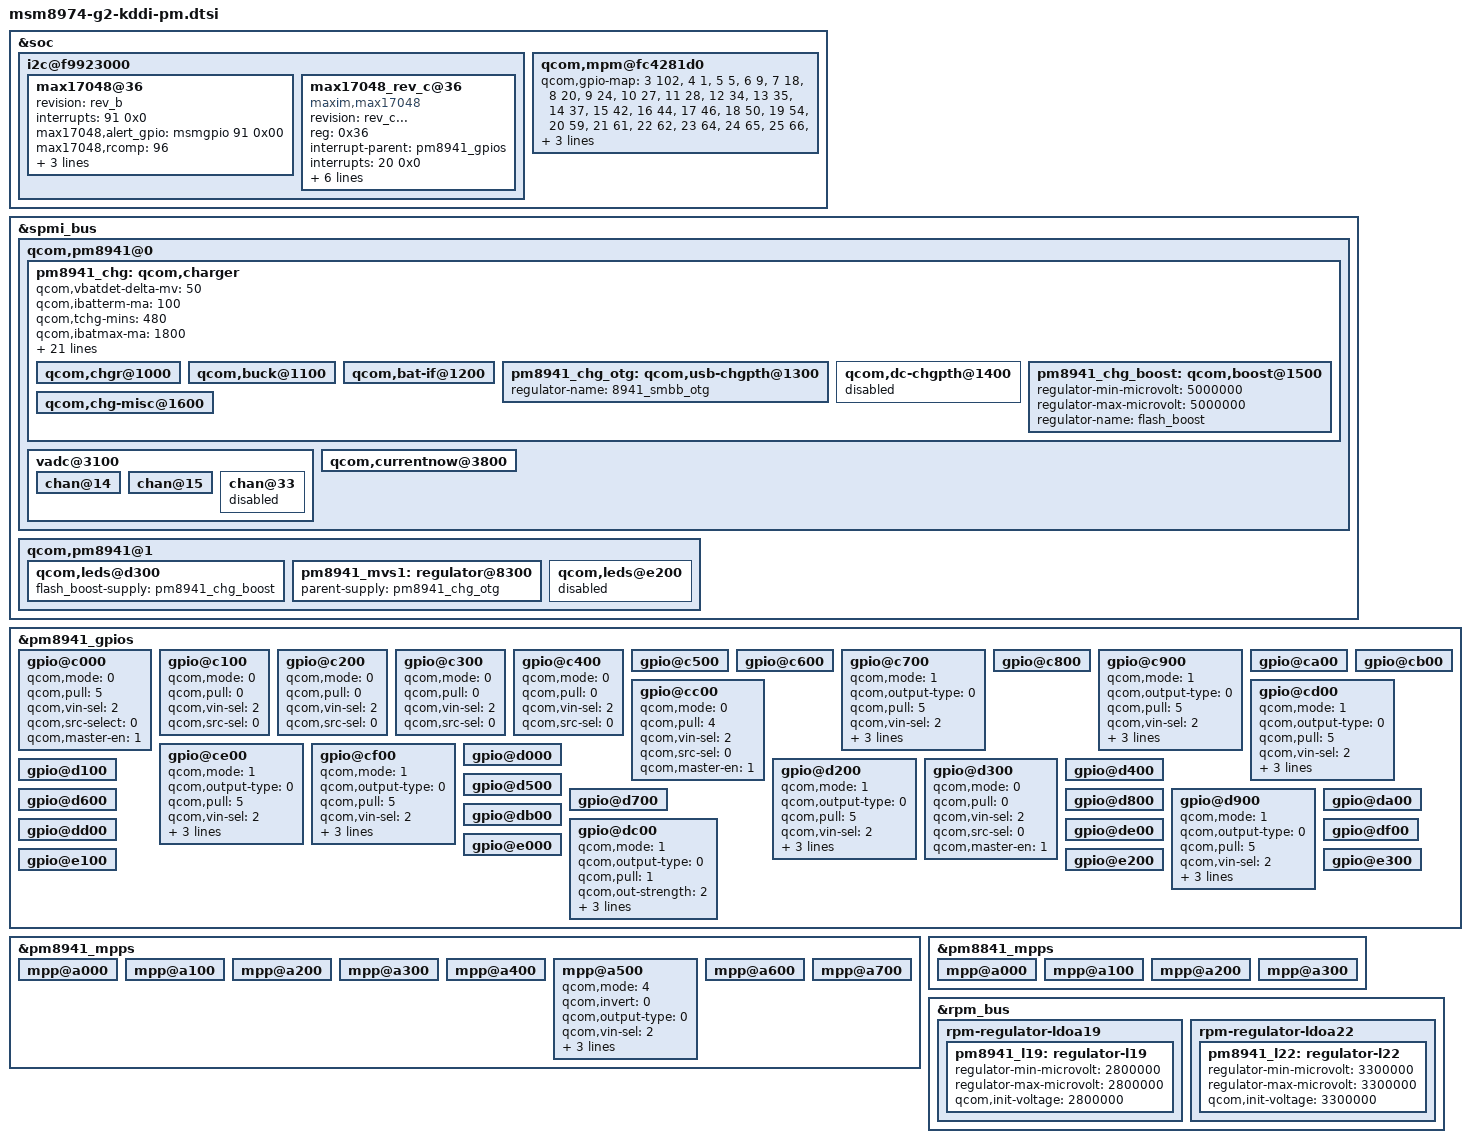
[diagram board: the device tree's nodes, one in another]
/* Copyright (c) 2012, Code Aurora Forum. All rights reserved.
 *
 * This program is free software; you can redistribute it and/or modify
* it under the terms of the GNU General Public License version 2 and
* only version 2 as published by the Free Software Foundation.
*
* This program is distributed in the hope that it will be useful,
* but WITHOUT ANY WARRANTY; without even the implied warranty of
* MERCHANTABILITY or FITNESS FOR A PARTICULAR PURPOSE.  See the
* GNU General Public License for more details.
*/

&soc {
	i2c@f9923000 {
		max17048@36 {
			status =  "ok";
			revision = "rev_b";
			interrupts = <91 0x0>;
			max17048,alert_gpio = <&msmgpio 91 0x00>;
			max17048,rcomp = <96>;
			max17048,temp_co_hot = <25>;
			max17048,temp_co_cold = <7400>;
			max17048,full_design = <2540>;
		};

		max17048_rev_c@36 {
			compatible = "maxim,max17048";
			status =  "ok";
			revision = "rev_c...";
			reg = <0x36>;
			interrupt-parent = <&pm8941_gpios>;
			interrupts = <20 0x0>;
			max17048,alert_gpio = <&pm8941_gpios 20 0x00>;
			max17048,alert_threshold = <2>;
			max17048,rcomp = <96>;
			max17048,temp_co_hot = <25>;
			max17048,temp_co_cold = <7400>;
			max17048,full_design = <2540>;
		};
	};

	qcom,mpm@fc4281d0 {
		/* overrides wakeup gpio source for NFC */
		qcom,gpio-map = <3  102>,
			<4  1 >,
			<5  5 >,
			<6  9 >,
			<7  18>,
			<8  20>,
			<9  24>,
			<10  27>,
			<11  28>,
			<12  34>,
			<13  35>,
			<14  37>,
			<15  42>,
			<16  44>,
			<17  46>,
			<18  50>,
			<19  54>,
			<20  59>,
			<21  61>,
			<22  62>,
			<23  64>,
			<24  65>,
			<25  66>,
			<26  67>,
			<27  68>,
			<28  71>,
			<29  72>,
			<30  73>,
			<31  74>,
			<32  75>,
			<33  77>,
			<34  79>,
			<35  80>,
			<36  82>,
			<37  86>,
			<38  92>,
			<39  93>,
			<40  95>,
			<41  144>,
			<42  94>; /* SNFC_IMA_INTU */
	};
};

&spmi_bus {
	qcom,pm8941@0 {
		pm8941_chg: qcom,charger {
			status = "ok";
			qcom,vbatdet-delta-mv = <50>;
			qcom,ibatterm-ma = <100>;
			qcom,tchg-mins = <480>;
			qcom,ibatmax-ma = <1800>;
			qcom,ibatsafe-ma = <1800>;
			qcom,vddmax-mv = <4350>;
			qcom,vddsafe-mv = <4380>;
			qcom,bpd-detection = "bpd_thm";
			qcom,duty-cycle-100p = <1>;
			otg-parent-supply = <&pm8941_boost>;

			lge,no-init-cable = <0 0 0>;
			lge,cable-mhl-1k = <5000 500 500>;
			lge,cable-u-28p7k = <5500 1600 500>;
			lge,cable-28p7k = <6000 1600 500>;
			lge,cable-56k = <200000 1500 1500>;
			lge,cable-100k = <239000 1600 500>;
			lge,cable-130k = <340000 1500 1500>;
			lge,cable-180k = <400000 1600 500>;
			lge,cable-200k = <410000 1600 500>;
			lge,cable-220k = <485000 1600 500>;
			lge,cable-270k = <560000 1600 500>;
			lge,cable-330k = <735000 1600 500>;
			lge,cable-620k = <955000 1600 500>;
			lge,cable-910k = <1140000 1500 1500>;
			lge,cable-none = <1900000 1600  500>;

			qcom,chgr@1000 {
				status = "ok";
			};

			qcom,buck@1100 {
				status = "ok";
			};

			qcom,bat-if@1200 {
				status = "ok";
			};

			pm8941_chg_otg: qcom,usb-chgpth@1300 {
				status = "ok";
				regulator-name = "8941_smbb_otg";
			};

			qcom,dc-chgpth@1400 {
				status = "disabled";
			};

			pm8941_chg_boost: qcom,boost@1500 {
				status = "ok";
				regulator-min-microvolt = <5000000>;
				regulator-max-microvolt = <5000000>;
				regulator-name = "flash_boost";
			};

			qcom,chg-misc@1600 {
				status = "ok";
			};

		};

		vadc@3100 {
			chan@14 {
				status = "ok";
			};
			chan@15 {
				status = "ok";
			};
			chan@33 {
				status = "disable";
			};
		};
		qcom,currentnow@3800 {
			status = "ok";
		};
	};

	qcom,pm8941@1 {
		qcom,leds@d300 {
			flash_boost-supply = <&pm8941_chg_boost>;
		};

		pm8941_mvs1: regulator@8300 {
			parent-supply = <&pm8941_chg_otg>;
		};

		qcom,leds@e200 {
			status = "disabled";
		};

	};
};

&pm8941_gpios {
	gpio@c000 { /* GPIO 1 */
		status = "ok";
		qcom,mode = <0>;
		qcom,pull = <5>;
		qcom,vin-sel = <2>;
		qcom,src-select = <0>;
		qcom,master-en = <1>;
	};

	gpio@c100 { /* GPIO 2 */
		qcom,mode = <0>;
		qcom,pull = <0>;
		qcom,vin-sel = <2>;
		qcom,src-sel = <0>;
	};

	gpio@c200 { /* GPIO 3 */
		qcom,mode = <0>;
		qcom,pull = <0>;
		qcom,vin-sel = <2>;
		qcom,src-sel = <0>;
	};

	gpio@c300 { /* GPIO 4 */
		qcom,mode = <0>;
		qcom,pull = <0>;
		qcom,vin-sel = <2>;
		qcom,src-sel = <0>;
	};

	gpio@c400 { /* GPIO 5 */
		qcom,mode = <0>;
		qcom,pull = <0>;
		qcom,vin-sel = <2>;
		qcom,src-sel = <0>;
	};

	gpio@c500 { /* GPIO 6 */
	};

	gpio@c600 { /* GPIO 7 */
	};

	gpio@c700 { /* GPIO 8 */
		status = "ok";
		qcom,mode = <1>;		/* QPNP_PIN_MODE_DIG_OUT */
		qcom,output-type = <0>;		/* QPNP_PIN_OUT_BUF_CMOS */
		qcom,pull = <5>;		/* QPNP_PIN_PULL_NO */
		qcom,vin-sel = <2>;		/* QPNP_PIN_VIN2 */
		qcom,out-strength = <2>;	/* QPNP_PIN_OUT_STRENGTH_MED */
		qcom,src-select = <0>;		/* QPNP_PIN_SEL_FUNC_CONSTANT */
		qcom,master-en = <1>;
	};

	gpio@c800 { /* GPIO 9 */
	};

	gpio@c900 { /* GPIO 10 */
		status = "ok";
		qcom,mode = <1>;		/* QPNP_PIN_MODE_DIG_OUT */
		qcom,output-type = <0>;		/* QPNP_PIN_OUT_BUF_CMOS */
		qcom,pull = <5>;		/* QPNP_PIN_PULL_NO */
		qcom,vin-sel = <2>;		/* QPNP_PIN_VIN2 */
		qcom,out-strength = <2>;	/* QPNP_PIN_OUT_STRENGTH_MED */
		qcom,src-select = <0>;		/* QPNP_PIN_SEL_FUNC_CONSTANT */
		qcom,master-en = <1>;
	};

	gpio@ca00 { /* GPIO 11 */
	};

	gpio@cb00 { /* GPIO 12 */
	};

	gpio@cc00 { /* GPIO 13 */ /* LGE_CHANGE, SlimPort Cable Det IRQ */
		status = "ok";
		qcom,mode = <0>;		/* QPNP_PIN_MODE_DIG_IN */
		qcom,pull = <4>;		/* QPNP_PIN_PULL_DN */
		qcom,vin-sel = <2>;		/* QPNP_PIN_VIN2 */
		qcom,src-sel = <0>;		/* QPNP_PIN_SEL_FUNC_CONSTANT */
		qcom,master-en = <1>;
	};

	gpio@cd00 { /* GPIO 14 */ /* LGE_CHANGE, SlimPort PWR Ctl Pin Setting */
		status = "ok";
		qcom,mode = <1>;		/* QPNP_PIN_MODE_DIG_OUT */
		qcom,output-type = <0>;		/* QPNP_PIN_OUT_BUF_CMOS */
		qcom,pull = <5>;		/* QPNP_PIN_PULL_NO */
		qcom,vin-sel = <2>;		/* QPNP_PIN_VIN2 */
		qcom,out-strength = <2>;	/* QPNP_PIN_OUT_STRENGTH_MED */
		qcom,src-sel = <0>;		/* QPNP_PIN_SEL_FUNC_CONSTANT */
		qcom,master-en = <1>;
	};

	gpio@ce00 { /* GPIO 15 */
		qcom,mode = <1>;
		qcom,output-type = <0>;
		qcom,pull = <5>;
		qcom,vin-sel = <2>;
		qcom,out-strength = <3>;
		qcom,src-sel = <2>;
		qcom,master-en = <1>;
	};

	gpio@cf00 { /* GPIO 16 */ /* LGE_CHANGE, [BT][younghyun.kwon@lge.com], 2013-02-26, BT Sleep clock(32KHz) configuration*/
		qcom,mode = <1>;
		qcom,output-type = <0>;
		qcom,pull = <5>;
		qcom,vin-sel = <2>;
		qcom,out-strength = <3>;
		qcom,src-sel = <3>;
		qcom,master-en = <1>;
	};

	gpio@d000 { /* GPIO 17 */
	};

	gpio@d100 { /* GPIO 18 */
	};

	gpio@d200 { /* GPIO 19 */
		qcom,mode = <1>;		/* QPNP_PIN_MODE_DIG_OUT */
		qcom,output-type = <0>;		/* QPNP_PIN_OUT_BUF_CMOS */
		qcom,pull = <5>;		/* QPNP_PIN_PULL_NO */
		qcom,vin-sel = <2>;		/* QPNP_PIN_VIN2 */
		qcom,out-strength = <2>;	/* QPNP_PIN_OUT_STRENGTH_MED */
		qcom,src-sel = <0>;		/* QPNP_PIN_SEL_FUNC_CONSTANT */
		qcom,master-en = <1>;
	};

	gpio@d300 { /* GPIO 20 */
		status = "ok";
		qcom,mode = <0>;		/* QPNP_PIN_MODE_DIG_IN */
		qcom,pull = <0>;		/* QPNP_PIN_PULL_UP_30 */
		qcom,vin-sel = <2>;		/* QPNP_PIN_VIN2 */
		qcom,src-sel = <0>;		/* QPNP_PIN_SEL_FUNC_CONSTANT */
		qcom,master-en = <1>;
	};

	gpio@d400 { /* GPIO 21 */
	};

	gpio@d500 { /* GPIO 22 */
	};

	gpio@d600 { /* GPIO 23 */
	};

	gpio@d700 { /* GPIO 24 */
	};

	gpio@d800 { /* GPIO 25 */
	};

	gpio@d900 { /* GPIO 26 */
		status = "ok";
		qcom,mode = <1>;		/* QPNP_PIN_MODE_DIG_OUT */
		qcom,output-type = <0>;		/* QPNP_PIN_OUT_BUF_CMOS */
		qcom,pull = <5>;		/* QPNP_PIN_PULL_NO */
		qcom,vin-sel = <2>;		/* QPNP_PIN_VIN2 */
		qcom,out-strength = <2>;	/* QPNP_PIN_OUT_STRENGTH_MED */
		qcom,src-select = <0>;		/* QPNP_PIN_SEL_FUNC_CONSTANT */
		qcom,master-en = <1>;
	};

	gpio@da00 { /* GPIO 27 */
	};

	gpio@db00 { /* GPIO 28 */
	};

	gpio@dc00 { /* GPIO 29 */
		status = "ok";
		qcom,mode = <1>;
		qcom,output-type = <0>;
		qcom,pull = <1>; /* set to default pull */
		qcom,out-strength = <2>;
		com,vin-sel = <2>; /* select 1.8 V source */
		qcom,src-select = <0>;      /* QPNP_PIN_SEL_FUNC_CONSTANT */
		qcom,master-en = <1>;
	};

	gpio@dd00 { /* GPIO 30 */
	};

	gpio@de00 { /* GPIO 31 */
	};

	gpio@df00 { /* GPIO 32 */
	};

	gpio@e000 { /* GPIO 33 */
	};

	gpio@e100 { /* GPIO 34 */
	};

	gpio@e200 { /* GPIO 35 */
	};

	gpio@e300 { /* GPIO 36 */
	};
};

&pm8941_mpps {

	mpp@a000 { /* MPP 1 */
	};

	mpp@a100 { /* MPP 2 */
	};

	mpp@a200 { /* MPP 3 */
	};

	mpp@a300 { /* MPP 4 */
	};

	mpp@a400 { /* MPP 5 */
		status = "ok";
	};

	mpp@a500 { /* MPP 6 */
		status = "ok";
		qcom,mode = <4>; /* QPNP_PIN_MODE_AIN */
		qcom,invert = <0>; /*no invert*/
		qcom,output-type = <0>; /* CMOS */
		qcom,vin-sel = <2>; /* PM8941_S3 1.8V > 1.6V */
		qcom,src-sel = <0>; /* CONSTANT */
		qcom,ain-route = <1>;
		qcom,master-en = <1>;
	};

	mpp@a600 { /* MPP 7 */
	};

	mpp@a700 { /* MPP 8 */
	};
};

&pm8841_mpps {

	mpp@a000 { /* MPP 1 */
	};

	mpp@a100 { /* MPP 2 */
	};

	mpp@a200 { /* MPP 3 */
	};

	mpp@a300 { /* MPP 4 */
	};
};

&rpm_bus {
    rpm-regulator-ldoa19 { /* IrDA */
        pm8941_l19: regulator-l19 {
            regulator-min-microvolt = <2800000>;
            regulator-max-microvolt = <2800000>;
            qcom,init-voltage = <2800000>;
        };
    };
    rpm-regulator-ldoa22 {
        pm8941_l22: regulator-l22 {
            regulator-min-microvolt = <3300000>;
            regulator-max-microvolt = <3300000>;
            qcom,init-voltage = <3300000>;
        };
    };
};
